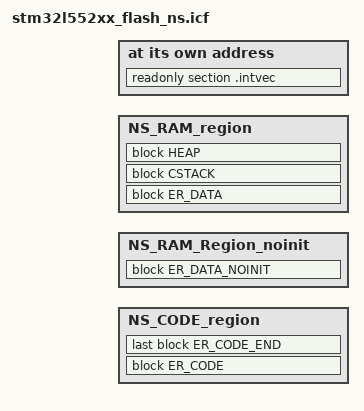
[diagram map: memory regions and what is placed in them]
#include "region_defs.h"

define memory mem with size = 4G;

define region S_CODE_region  =   mem:[from S_CODE_START size S_CODE_SIZE];
define region NS_CODE_region =   mem:[from NS_CODE_START size NS_CODE_SIZE];

define region S_RAM_region   =  mem:[from S_DATA_START size S_DATA_SIZE];
define region NS_RAM_Region_noinit = mem:[from NS_DATA_START size NS_NO_INIT_DATA_SIZE];
define region NS_RAM_region  =  mem:[from (NS_DATA_START+NS_NO_INIT_DATA_SIZE) size (NS_DATA_SIZE-NS_NO_INIT_DATA_SIZE)];


define block CSTACK	with alignment = 8, size = NS_PSP_STACK_SIZE { };
define block HEAP       	with alignment = 8, size = NS_HEAP_SIZE { };
define block ER_DATA_NOINIT { section .noinit};
define block ER_CODE		with alignment = 8 {readonly};
define block ER_CODE_END with alignment = 32, size = 0 { };

place at address mem:NS_CODE_START { readonly section .intvec };
define block ER_DATA with maximum size = 0x10000, alignment = 8 {readwrite};

do not initialize  { section .noinit };
initialize by copy { readwrite };
if (isdefinedsymbol(__USE_DLIB_PERTHREAD))
{
  // Required in a multi-threaded application
  initialize by copy with packing = none { section __DLIB_PERTHREAD };
}

place in NS_CODE_region  { block ER_CODE , last block ER_CODE_END,};
place in NS_RAM_Region_noinit  { block  ER_DATA_NOINIT };
place in NS_RAM_region   { block ER_DATA, block CSTACK, block HEAP };
